# CY8C5868AXI_LP035 register map
File version: 0.1
Registers are 32-bit, read-write, no defined reset value unless marked. A register's access mark holds for its fields unless they carry their own. Offsets are from the block's base; [hi:lo] are bit positions; {n}, {i} and the like mark numbered series; 'fields as' and 'values as' point back to an identical list.

## power_comp
Base 0x00000000
0x400043A7 power_comp_Comp_PM_ACT_CFG 8-bit — Active Power Mode Configuration Register 7
  [3:0] en_cmp — Enable comparator. Populated subsystems are counted from the LSB, for example bit 0 corresponds to comparator 0
0x400043B7 power_comp_Comp_PM_STBY_CFG 8-bit — Standby Power Mode Configuration Register 7
  fields as power_comp_Comp_PM_ACT_CFG
0x40004632 power_comp_Comp_TR0 8-bit — Comparator Trim Register_TR0
  [4:0] trimA_4_0_ — Sets the trim value to be added to the P-type load for offset calibration
    0=TRIMA_0 (Does not add any offset); {v}=TRIMA_POS_SIDE_{v} (Adds offset of ~{v}mV to the positive side) (v=1..8); {v}=TRIMA_NEG_SIDE_{v-9} (Adds offset of ~{v-10}mV to the negative side) (v=10..18)
0x40004633 power_comp_Comp_TR1 8-bit — Comparator Trim Register_TR1
  [4:0] trimB_4_0_ — Sets the trim value to be added to the N-type load for offset calibration
    0=TRIMB_0 (Does not add any offset); {v}=TRIMB_NEG_SIDE_{v} (Adds offset of ~{v}mV to the negative side) (v=1..8); 10=TRIMB_9 (Does not add any offset); {v}=TRIMB_POS_SIDE_{v-10} (Adds offset of ~{v-10}mV to the positive side) (v=11..18)
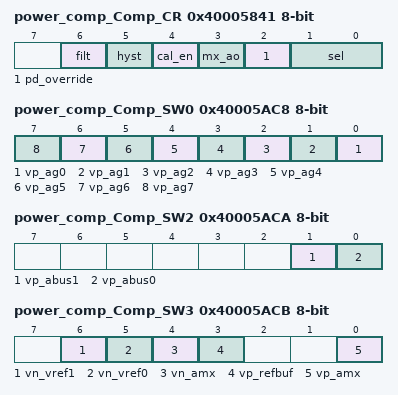
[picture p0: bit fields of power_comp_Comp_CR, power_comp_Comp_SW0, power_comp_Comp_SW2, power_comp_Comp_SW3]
0x40005841 power_comp_Comp_CR 8-bit — Comparator Control Register
  [6] filt — enables a glitch filter at the output of the comparator
    0=FILT_DISABLE (Disable glitch filter); 1=FILT_ENABLE (Enable glitch filter)
  [5] hyst — enables a hysteresis of 10mV typ
    1=HYST_DISABLE (Disable hysteresis); 0=HYST_ENABLE (Enable hysteresis)
  [4] cal_en — enables shorting of the two comparator inputs for trim calibration purposes
    0=CAL_EN_DISABLE (Disable calibration); 1=CAL_EN_ENABLE (Enable calibration)
  [3] mx_ao — comparator sleep always-on logic mux control
    0=MX_AO_BYPASS (Bypass comparator sleep always-on logic); 1=MX_AO_ENABLE (Enable comparator sleep always-on logic)
  [2] pd_override — Power down override to allow comparator to continue operating during sleep
    0=PD_OVERRIDE_DISABLE (Don't override power down); 1=PD_OVERRIDE_ENABLE (Override power down)
  [1:0] sel — Selects the mode of operation of the comparator
    0=SEL_SLOW (slow mode); 1=SEL_FAST (fast mode); 2=SEL_LP (ultra low power mode); 3=SEL_ILLEGAL (Illegal Mode)
0x40005AC8 power_comp_Comp_SW0 8-bit — Comparator Analog Routing Register 0
  [all] fields
    0=AG_NC (not connected); 1=AG_CONNECTED (Connect to Analog Global)
  [n] vp_ag{n} (n=0..7) — Connect positive voltage input to analog global of same side
0x40005ACA power_comp_Comp_SW2 8-bit — Comparator Analog Routing Register 2
  [1] vp_abus1 — Connect positive voltage input to analog (local) bus of the same side
    0=ABUS_NC (not connected); 1=ABUS_CONNECTED (Connect to Analog (local) Bus)
  [0] vp_abus0 — Connect positive voltage input to analog (local) bus of the same side
    values as vp_abus1
0x40005ACB power_comp_Comp_SW3 8-bit — Comparator Analog Routing Register 3
  [6] vn_vref1 — Connect negative voltage input to Voltage Reference 1
    0=VREF_NC (not connected); 1=VREF_CONNECTED (Connect to Voltage Reference)
  [5] vn_vref0 — Connect negative voltage input to Voltage Reference 0
    values as vn_vref1
  [4] vn_amx — Connect negative voltage input to Analog Mux Bus
    0=AMX_NC (not connected); 1=AMX_CONNECTED (Connect to AMUXBUS)
  [3] vp_refbuf — Connect positive voltage input to CapSense reference buffer channel
    0=VP_REFBUF_ENABLED (disable); 1=VP_REFBUF_DISABLED (enable)
  [0] vp_amx — Connect positive voltage input to Analog Mux Bus
    values as vn_amx
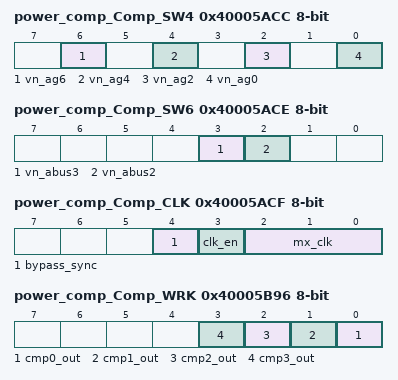
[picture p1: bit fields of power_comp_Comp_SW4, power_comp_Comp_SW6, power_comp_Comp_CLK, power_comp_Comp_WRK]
0x40005ACC power_comp_Comp_SW4 8-bit — Comparator Analog Routing Register 4
  [all] fields
    values as the fields of power_comp_Comp_SW0
  [6] vn_ag6 — Connect negative voltage input to analog global of same side
  [4] vn_ag4 — Connect negative voltage input to analog global of same side
  [2] vn_ag2 — Connect negative voltage input to analog global of same side
  [0] vn_ag0 — Connect negative voltage input to analog global of same side
0x40005ACE power_comp_Comp_SW6 8-bit — Comparator Analog Routing Register 6
  [3] vn_abus3 — Connect negative voltage input to analog (local) bus of the same side
    values as power_comp_Comp_SW2.vp_abus1
  [2] vn_abus2 — Connect negative voltage input to analog (local) bus of the same side
    values as power_comp_Comp_SW2.vp_abus1
0x40005ACF power_comp_Comp_CLK 8-bit — Comparator Clock Control Register
  [4] bypass_sync — Bypass Synchronization
    0=Synchronization not bypassed (Synchronization enabled); 1=Synchronization bypassed (Synchronization disabled)
  [3] clk_en — Clock gating control
    0=disable clock; 1=enable clock
  [2:0] mx_clk — Clock Selection
    {v}=Select clk_a{v} and clk_a{v}_dig (v=0..3); 4=Select UDB generated clock
0x40005B96 power_comp_Comp_WRK 8-bit — Comparator output working register
  [n] cmp{n}_out ro (n=0..3) — Comparator Output

## USBUART_1 — USBFS
Base 0x00000000
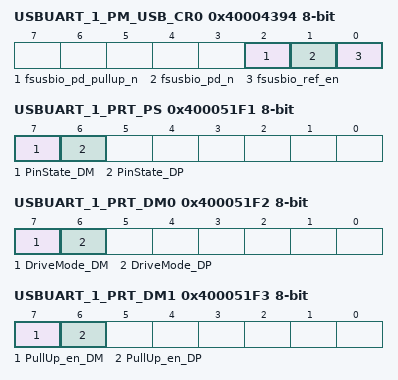
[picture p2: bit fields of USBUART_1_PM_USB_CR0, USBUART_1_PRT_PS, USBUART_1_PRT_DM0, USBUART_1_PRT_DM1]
0x40004394 USBUART_1_PM_USB_CR0 8-bit — USB Power Mode Control Register 0
  [2] fsusbio_pd_pullup_n, [1] fsusbio_pd_n, [0] fsusbio_ref_en
0x400043A5 USBUART_1_PM_ACT_CFG 8-bit — Active Power Mode Configuration Register
0x400043B5 USBUART_1_PM_STBY_CFG 8-bit — Standby Power Mode Configuration Register
0x400051F1 USBUART_1_PRT_PS 8-bit — Port Pin State Register
  [7] PinState_DM ro, [6] PinState_DP ro
0x400051F2 USBUART_1_PRT_DM0 8-bit — Port Drive Mode Register
  [7] DriveMode_DM, [6] DriveMode_DP
0x400051F3 USBUART_1_PRT_DM1 8-bit — Port Drive Mode Register
  [7] PullUp_en_DM, [6] PullUp_en_DP
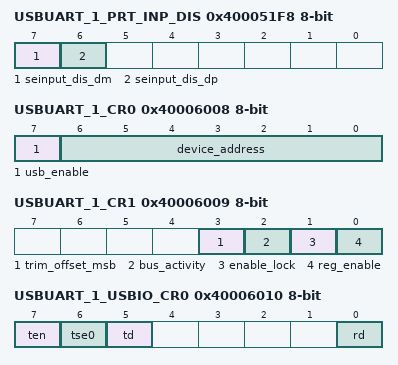
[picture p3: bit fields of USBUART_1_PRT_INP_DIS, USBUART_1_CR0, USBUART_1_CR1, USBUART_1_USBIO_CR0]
0x400051F8 USBUART_1_PRT_INP_DIS 8-bit — Input buffer disable override
  [7] seinput_dis_dm, [6] seinput_dis_dp
0x40006000 USBUART_1_EP0_DR0 8-bit — bmRequestType
0x40006001 USBUART_1_EP0_DR1 8-bit — bRequest
0x40006002 USBUART_1_EP0_DR2 8-bit — wValueLo
0x40006003 USBUART_1_EP0_DR3 8-bit — wValueHi
0x40006004 USBUART_1_EP0_DR4 8-bit — wIndexLo
0x40006005 USBUART_1_EP0_DR5 8-bit — wIndexHi
0x40006006 USBUART_1_EP0_DR6 8-bit — lengthLo
0x40006007 USBUART_1_EP0_DR7 8-bit — lengthHi
0x40006008 USBUART_1_CR0 8-bit — USB Control Register 0
  [7] usb_enable, [6:0] device_address ro
0x40006009 USBUART_1_CR1 8-bit — USB Control Register 1
  [3] trim_offset_msb, [2] bus_activity, [1] enable_lock, [0] reg_enable
{0x40005FFE+0x10*i} USBUART_1_SIE_EP{i}_CR0 8-bit (i=1..8) — The Endpoint{i} Control Register
0x40006010 USBUART_1_USBIO_CR0 8-bit — USBIO Control Register 0
  [7] ten, [6] tse0, [5] td, [0] rd ro
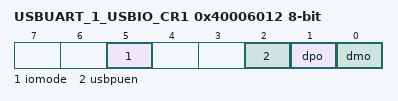
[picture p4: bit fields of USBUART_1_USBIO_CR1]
0x40006012 USBUART_1_USBIO_CR1 8-bit — USBIO Control Register 1
  [5] iomode, [2] usbpuen, [1] dpo ro, [0] dmo ro
0x4000608C USBUART_1_BUF_SIZE 8-bit — Dedicated Endpoint Buffer Size Register
0x4000608E USBUART_1_EP_ACTIVE 8-bit — Endpoint Active Indication Register
0x4000608F USBUART_1_EP_TYPE 8-bit — Endpoint Type (IN/OUT) Indication
0x4000609D USBUART_1_USB_CLK_EN 8-bit — USB Block Clock Enable Register

## millis_timer
Base 0x00000000
0x40006404 millis_timer_COUNTER 24-bit — UDB.A0 - Current Down Counter Value
0x40006424 millis_timer_PERIOD 24-bit — UDB.D0 - Assigned Period
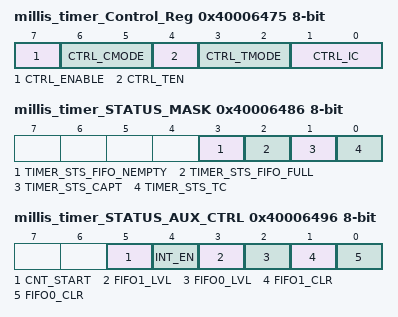
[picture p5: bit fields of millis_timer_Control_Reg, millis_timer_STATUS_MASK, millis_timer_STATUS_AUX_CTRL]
0x40006475 millis_timer_Control_Reg 8-bit — UDB Control Register - Assigned Control Register Value
  [7] CTRL_ENABLE — Enable the Timer
  [6:5] CTRL_CMODE — Capture Mode
  [4] CTRL_TEN — Trigger Enable Bit
  [3:2] CTRL_TMODE — Trigger Mode
  [1:0] CTRL_IC — Interrupt Count
0x40006486 millis_timer_STATUS_MASK 8-bit — UDB Status bits Interrupt Mask Enable Register
  [3] TIMER_STS_FIFO_NEMPTY ro — FIFO Empty status
  [2] TIMER_STS_FIFO_FULL ro — FIFO Full Status
  [1] TIMER_STS_CAPT ro — Enables the Interrupt on Capture
  [0] TIMER_STS_TC ro — Enables the Interrupt on TC
0x40006496 millis_timer_STATUS_AUX_CTRL 8-bit — UDB Auxilliary Control Register
  [5] CNT_START — FIFO0 clear
    0=E_CNT_START0 (Disable counter); 1=E_CNT_START1 (Enable counter)
  [4] INT_EN
    0=E_INT_EN0 (Interrupt disabled); 1=E_INT_EN1 (Interrupt enabled)
  [3] FIFO1_LVL — FIFO level
    0=E_FIFO_LVL_0 (FIFO LVL: input mode: FIFO not full; output mode: FIFO not empty); 1=E_FIFO_LVL_1 (FIFO LVL: input mode: FIFO at least 1/2 empty; output mode: FIFO at least 1/2 full)
  [2] FIFO0_LVL — FIFO level
    values as FIFO1_LVL
  [1] FIFO1_CLR — FIFO1 clear
    0=E_FIFO_CLR_0 (Normal FIFO operation); 1=E_FIFO_CLR_1 (Clear FIFO state)
  [0] FIFO0_CLR — FIFO0 clear
    values as FIFO1_CLR
